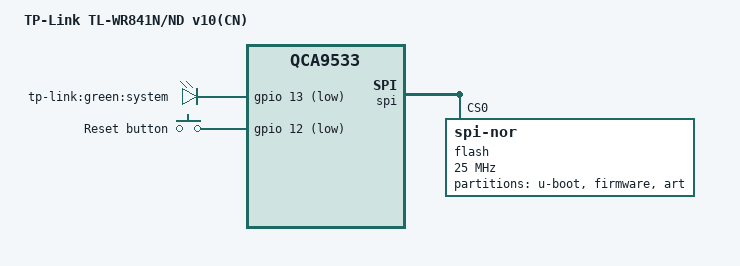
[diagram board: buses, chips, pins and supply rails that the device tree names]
// SPDX-License-Identifier: GPL-2.0-or-later OR MIT
/dts-v1/;

#include "qca9533_tplink_tl-wr841.dtsi"

/ {
	compatible = "tplink,tl-wr841-v10-CN", "qca,qca9533";
	model = "TP-Link TL-WR841N/ND v10(CN)";

	aliases {
		led-boot = &system_led;
		led-failsafe = &system_led;
		led-running = &system_led;
		led-upgrade = &system_led;
	};

	gpio_leds: leds {
		compatible = "gpio-leds";

		system_led: system {
			label = "tp-link:green:system";
			gpios = <&gpio 13 GPIO_ACTIVE_LOW>;
		};
	};

	keys {
		compatible = "gpio-keys";

		reset {
			label = "Reset button";
			linux,code = <KEY_RESTART>;
			gpios = <&gpio 12 GPIO_ACTIVE_LOW>;
			debounce-interval = <60>;
		};
	};
};

&spi {
	status = "okay";
	num-cs = <1>;

	flash@0 {
		compatible = "jedec,spi-nor";
		reg = <0>;
		spi-max-frequency = <25000000>;

		partitions {
			compatible = "fixed-partitions";
			#address-cells = <1>;
			#size-cells = <1>;

			uboot:	partition@0 {
				label = "u-boot";
				reg = <0x000000 0x020000>;
				read-only;
			};

			partition@20000 {
				compatible = "tplink,firmware";
				label = "firmware";
				reg = <0x020000 0xfd0000>;
			};

			art: partition@ff0000 {
				label = "art";
				reg = <0xff0000 0x010000>;
				read-only;
			};
		};
	};
};
